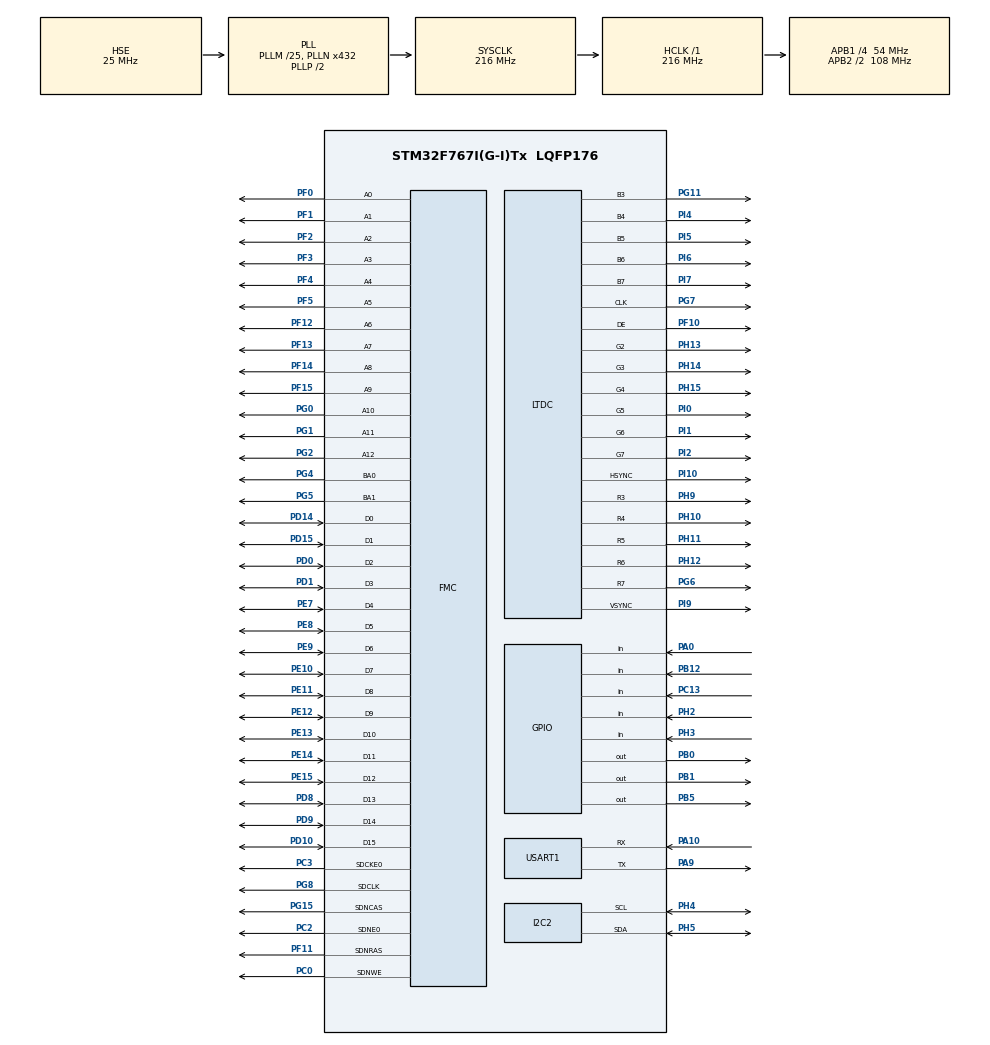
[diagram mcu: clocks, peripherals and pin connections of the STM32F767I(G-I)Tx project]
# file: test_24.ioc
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CORTEX_M7.MPU_Control=__NULL
CORTEX_M7.default_mode_Activation=1
DMA2D.ColorMode=DMA2D_OUTPUT_RGB565
FMC.CASLatency1=FMC_SDRAM_CAS_LATENCY_3
FMC.ColumnBitsNumber1=FMC_SDRAM_COLUMN_BITS_NUM_9
FMC.ExitSelfRefreshDelay1=8
FMC.LoadToActiveDelay1=2
FMC.RCDDelay1=2
FMC.RPDelay1=2
FMC.ReadBurst1=FMC_SDRAM_RBURST_ENABLE
FMC.ReadPipeDelay1=FMC_SDRAM_RPIPE_DELAY_1
FMC.RowCycleDelay1=6
FMC.SDClockPeriod1=FMC_SDRAM_CLOCK_PERIOD_2
FMC.SelfRefreshTime1=6
FMC.WriteRecoveryTime1=4
I2C2.I2C_Fall_Time=10
I2C2.I2C_Rise_Time=100
I2C2.Timing=0x60201E2B
LTDC.ActiveW=800
LTDC.Alpha_L0=255
LTDC.BlendingFactor1_L0=LTDC_BLENDING_FACTOR1_PAxCA
LTDC.BlendingFactor2_L0=LTDC_BLENDING_FACTOR2_PAxCA
LTDC.FBStartAdress_L0=0xc0000000
LTDC.HBP=88
LTDC.HFP=40
LTDC.HSync=48
LTDC.ImageHeight_L0=480
LTDC.ImageWidth_L0=800
LTDC.ImageWidth_L1=0
LTDC.PixelFormat_L0=LTDC_PIXEL_FORMAT_RGB565
LTDC.PixelFormat_L1=LTDC_PIXEL_FORMAT_RGB565
LTDC.VBP=32
LTDC.VFP=13
LTDC.VSync=3
LTDC.WindowX1_L0=800
LTDC.WindowY1_L0=480
Mcu.Family=STM32F7
Mcu.Name=STM32F767I(G-I)Tx
Mcu.Package=LQFP176
NVIC.PriorityGroup=NVIC_PRIORITYGROUP_2
NVIC.USART1_IRQn=true\:2\:2\:true\:false\:true\:true\:true\:true
PA0/WKUP.GPIO_PuPd=GPIO_PULLDOWN
PA0/WKUP.Signal=GPIO_Input
PA10.GPIO_PuPd=GPIO_PULLUP
PA10.GPIO_Speed=GPIO_SPEED_FREQ_HIGH
PA10.Mode=Asynchronous
PA10.Signal=USART1_RX
PA9.GPIO_ModeDefaultPP=GPIO_MODE_AF_PP
PA9.GPIO_PuPd=GPIO_PULLUP
PA9.GPIO_Speed=GPIO_SPEED_FREQ_HIGH
PA9.Mode=Asynchronous
PA9.Signal=USART1_TX
PB0.GPIO_PuPd=GPIO_PULLUP
PB0.GPIO_Speed=GPIO_SPEED_FREQ_HIGH
PB0.PinState=GPIO_PIN_SET
PB0.Signal=GPIO_Output
PB1.GPIO_PuPd=GPIO_PULLUP
PB1.GPIO_Speed=GPIO_SPEED_FREQ_HIGH
PB1.PinState=GPIO_PIN_SET
PB1.Signal=GPIO_Output
PB12.GPIO_PuPd=GPIO_PULLUP
PB12.Signal=GPIO_Input
PB5.GPIO_PuPd=GPIO_PULLUP
PB5.GPIO_Speed=GPIO_SPEED_FREQ_HIGH
PB5.Signal=GPIO_Output
PC0.GPIO_Mode=GPIO_MODE_AF_PP
PC0.GPIO_PuPd=GPIO_PULLUP
PC0.GPIO_Speed_High_Default=GPIO_SPEED_FREQ_HIGH
PC0.Signal=FMC_SDNWE
PC13.GPIO_Mode=GPIO_MODE_INPUT
PC13.GPIO_PuPd=GPIO_PULLUP
PC13.Signal=GPIO_Input
PC14/OSC32_IN.Mode=LSE-External-Oscillator
PC14/OSC32_IN.Signal=RCC_OSC32_IN
PC15/OSC32_OUT.Mode=LSE-External-Oscillator
PC15/OSC32_OUT.Signal=RCC_OSC32_OUT
PC2.GPIO_Mode=GPIO_MODE_AF_PP
PC2.GPIO_PuPd=GPIO_PULLUP
PC2.GPIO_Speed_High_Default=GPIO_SPEED_FREQ_HIGH
PC2.Mode=SdramChipSelect1_1
PC2.Signal=FMC_SDNE0
PC3.GPIO_Mode=GPIO_MODE_AF_PP
PC3.GPIO_PuPd=GPIO_PULLUP
PC3.GPIO_Speed_High_Default=GPIO_SPEED_FREQ_HIGH
PC3.Mode=SdramChipSelect1_1
PC3.Signal=FMC_SDCKE0
PD0.GPIO_Mode=GPIO_MODE_AF_PP
PD0.GPIO_PuPd=GPIO_PULLUP
PD0.GPIO_Speed_High_Default=GPIO_SPEED_FREQ_HIGH
PD0.Signal=FMC_D2_DA2
PD1.GPIO_Mode=GPIO_MODE_AF_PP
PD1.GPIO_PuPd=GPIO_PULLUP
PD1.GPIO_Speed_High_Default=GPIO_SPEED_FREQ_HIGH
PD1.Signal=FMC_D3_DA3
PD10.GPIO_Mode=GPIO_MODE_AF_PP
PD10.GPIO_PuPd=GPIO_PULLUP
PD10.GPIO_Speed_High_Default=GPIO_SPEED_FREQ_HIGH
PD10.Signal=FMC_D15_DA15
PD14.GPIO_Mode=GPIO_MODE_AF_PP
PD14.GPIO_PuPd=GPIO_PULLUP
PD14.GPIO_Speed_High_Default=GPIO_SPEED_FREQ_HIGH
PD14.Signal=FMC_D0_DA0
PD15.GPIO_Mode=GPIO_MODE_AF_PP
PD15.GPIO_PuPd=GPIO_PULLUP
PD15.GPIO_Speed_High_Default=GPIO_SPEED_FREQ_HIGH
PD15.Signal=FMC_D1_DA1
PD8.GPIO_Mode=GPIO_MODE_AF_PP
PD8.GPIO_PuPd=GPIO_PULLUP
PD8.GPIO_Speed_High_Default=GPIO_SPEED_FREQ_HIGH
PD8.Signal=FMC_D13_DA13
PD9.GPIO_Mode=GPIO_MODE_AF_PP
PD9.GPIO_PuPd=GPIO_PULLUP
PD9.GPIO_Speed_High_Default=GPIO_SPEED_FREQ_HIGH
PD9.Signal=FMC_D14_DA14
PE0.GPIO_Mode=GPIO_MODE_AF_PP
PE0.GPIO_PuPd=GPIO_PULLUP
PE0.GPIO_Speed_High_Default=GPIO_SPEED_FREQ_HIGH
PE0.Signal=FMC_NBL0
PE1.GPIO_Mode=GPIO_MODE_AF_PP
PE1.GPIO_PuPd=GPIO_PULLUP
PE1.GPIO_Speed_High_Default=GPIO_SPEED_FREQ_HIGH
PE1.Signal=FMC_NBL1
PE10.GPIO_Mode=GPIO_MODE_AF_PP
PE10.GPIO_PuPd=GPIO_PULLUP
PE10.GPIO_Speed_High_Default=GPIO_SPEED_FREQ_HIGH
PE10.Signal=FMC_D7_DA7
PE11.GPIO_Mode=GPIO_MODE_AF_PP
PE11.GPIO_PuPd=GPIO_PULLUP
PE11.GPIO_Speed_High_Default=GPIO_SPEED_FREQ_HIGH
PE11.Signal=FMC_D8_DA8
PE12.GPIO_Mode=GPIO_MODE_AF_PP
PE12.GPIO_PuPd=GPIO_PULLUP
PE12.GPIO_Speed_High_Default=GPIO_SPEED_FREQ_HIGH
PE12.Signal=FMC_D9_DA9
PE13.GPIO_Mode=GPIO_MODE_AF_PP
PE13.GPIO_PuPd=GPIO_PULLUP
PE13.GPIO_Speed_High_Default=GPIO_SPEED_FREQ_HIGH
PE13.Signal=FMC_D10_DA10
PE14.GPIO_Mode=GPIO_MODE_AF_PP
PE14.GPIO_PuPd=GPIO_PULLUP
PE14.GPIO_Speed_High_Default=GPIO_SPEED_FREQ_HIGH
PE14.Signal=FMC_D11_DA11
PE15.GPIO_Mode=GPIO_MODE_AF_PP
PE15.GPIO_PuPd=GPIO_PULLUP
PE15.GPIO_Speed_High_Default=GPIO_SPEED_FREQ_HIGH
PE15.Signal=FMC_D12_DA12
PE7.GPIO_Mode=GPIO_MODE_AF_PP
PE7.GPIO_PuPd=GPIO_PULLUP
PE7.GPIO_Speed_High_Default=GPIO_SPEED_FREQ_HIGH
PE7.Signal=FMC_D4_DA4
PE8.GPIO_Mode=GPIO_MODE_AF_PP
PE8.GPIO_PuPd=GPIO_PULLUP
PE8.GPIO_Speed_High_Default=GPIO_SPEED_FREQ_HIGH
PE8.Signal=FMC_D5_DA5
PE9.GPIO_Mode=GPIO_MODE_AF_PP
PE9.GPIO_PuPd=GPIO_PULLUP
PE9.GPIO_Speed_High_Default=GPIO_SPEED_FREQ_HIGH
PE9.Signal=FMC_D6_DA6
PF0.GPIO_Mode=GPIO_MODE_AF_PP
PF0.GPIO_PuPd=GPIO_PULLUP
PF0.GPIO_Speed_High_Default=GPIO_SPEED_FREQ_HIGH
PF0.Signal=FMC_A0
PF1.GPIO_Mode=GPIO_MODE_AF_PP
PF1.GPIO_PuPd=GPIO_PULLUP
PF1.GPIO_Speed_High_Default=GPIO_SPEED_FREQ_HIGH
PF1.Signal=FMC_A1
PF10.GPIO_PuPd=GPIO_NOPULL
PF10.GPIO_Speed=GPIO_SPEED_FREQ_HIGH
PF10.Mode=RGB565
PF10.Signal=LTDC_DE
PF11.GPIO_Mode=GPIO_MODE_AF_PP
PF11.GPIO_PuPd=GPIO_PULLUP
PF11.GPIO_Speed_High_Default=GPIO_SPEED_FREQ_HIGH
PF11.Signal=FMC_SDNRAS
PF12.GPIO_Mode=GPIO_MODE_AF_PP
PF12.GPIO_PuPd=GPIO_PULLUP
PF12.GPIO_Speed_High_Default=GPIO_SPEED_FREQ_HIGH
PF12.Signal=FMC_A6
PF13.GPIO_Mode=GPIO_MODE_AF_PP
PF13.GPIO_PuPd=GPIO_PULLUP
PF13.GPIO_Speed_High_Default=GPIO_SPEED_FREQ_HIGH
PF13.Signal=FMC_A7
PF14.GPIO_Mode=GPIO_MODE_AF_PP
PF14.GPIO_PuPd=GPIO_PULLUP
PF14.GPIO_Speed_High_Default=GPIO_SPEED_FREQ_HIGH
PF14.Signal=FMC_A8
PF15.GPIO_Mode=GPIO_MODE_AF_PP
PF15.GPIO_PuPd=GPIO_PULLUP
PF15.GPIO_Speed_High_Default=GPIO_SPEED_FREQ_HIGH
PF15.Signal=FMC_A9
PF2.GPIO_Mode=GPIO_MODE_AF_PP
PF2.GPIO_PuPd=GPIO_PULLUP
PF2.GPIO_Speed_High_Default=GPIO_SPEED_FREQ_HIGH
PF2.Signal=FMC_A2
PF3.GPIO_Mode=GPIO_MODE_AF_PP
PF3.GPIO_PuPd=GPIO_PULLUP
PF3.GPIO_Speed_High_Default=GPIO_SPEED_FREQ_HIGH
PF3.Signal=FMC_A3
PF4.GPIO_Mode=GPIO_MODE_AF_PP
PF4.GPIO_PuPd=GPIO_PULLUP
PF4.GPIO_Speed_High_Default=GPIO_SPEED_FREQ_HIGH
PF4.Signal=FMC_A4
PF5.GPIO_Mode=GPIO_MODE_AF_PP
PF5.GPIO_PuPd=GPIO_PULLUP
PF5.GPIO_Speed_High_Default=GPIO_SPEED_FREQ_HIGH
PF5.Signal=FMC_A5
PG0.GPIO_Mode=GPIO_MODE_AF_PP
PG0.GPIO_PuPd=GPIO_PULLUP
PG0.GPIO_Speed_High_Default=GPIO_SPEED_FREQ_HIGH
PG0.Signal=FMC_A10
PG1.GPIO_Mode=GPIO_MODE_AF_PP
PG1.GPIO_PuPd=GPIO_PULLUP
PG1.GPIO_Speed_High_Default=GPIO_SPEED_FREQ_HIGH
PG1.Signal=FMC_A11
PG11.GPIO_Mode=GPIO_MODE_AF_PP
PG11.GPIO_PuPd=GPIO_NOPULL
PG11.GPIO_Speed=GPIO_SPEED_FREQ_HIGH
PG11.Mode=RGB565
PG11.Signal=LTDC_B3
PG15.GPIO_Mode=GPIO_MODE_AF_PP
PG15.GPIO_PuPd=GPIO_PULLUP
PG15.GPIO_Speed_High_Default=GPIO_SPEED_FREQ_HIGH
PG15.Signal=FMC_SDNCAS
PG2.GPIO_Mode=GPIO_MODE_AF_PP
PG2.GPIO_PuPd=GPIO_PULLUP
PG2.GPIO_Speed_High_Default=GPIO_SPEED_FREQ_HIGH
PG2.Signal=FMC_A12
PG4.GPIO_Mode=GPIO_MODE_AF_PP
PG4.GPIO_PuPd=GPIO_PULLUP
PG4.GPIO_Speed_High_Default=GPIO_SPEED_FREQ_HIGH
PG4.Signal=FMC_A14_BA0
PG5.GPIO_Mode=GPIO_MODE_AF_PP
PG5.GPIO_PuPd=GPIO_PULLUP
PG5.GPIO_Speed_High_Default=GPIO_SPEED_FREQ_HIGH
PG5.Signal=FMC_A15_BA1
PG6.GPIO_Mode=GPIO_MODE_AF_PP
PG6.GPIO_PuPd=GPIO_NOPULL
PG6.GPIO_Speed=GPIO_SPEED_FREQ_HIGH
PG6.Mode=RGB565
PG6.Signal=LTDC_R7
PG7.GPIO_Mode=GPIO_MODE_AF_PP
PG7.GPIO_PuPd=GPIO_NOPULL
PG7.GPIO_Speed=GPIO_SPEED_FREQ_HIGH
PG7.Mode=RGB565
PG7.Signal=LTDC_CLK
PG8.GPIO_Mode=GPIO_MODE_AF_PP
PG8.GPIO_PuPd=GPIO_PULLUP
PG8.GPIO_Speed_High_Default=GPIO_SPEED_FREQ_HIGH
PG8.Signal=FMC_SDCLK
PH0/OSC_IN.Mode=HSE-External-Oscillator
PH0/OSC_IN.Signal=RCC_OSC_IN
PH1/OSC_OUT.Mode=HSE-External-Oscillator
PH1/OSC_OUT.Signal=RCC_OSC_OUT
PH10.GPIO_Mode=GPIO_MODE_AF_PP
PH10.GPIO_PuPd=GPIO_NOPULL
PH10.GPIO_Speed=GPIO_SPEED_FREQ_HIGH
PH10.Mode=RGB565
PH10.Signal=LTDC_R4
PH11.GPIO_Mode=GPIO_MODE_AF_PP
PH11.GPIO_PuPd=GPIO_NOPULL
PH11.GPIO_Speed=GPIO_SPEED_FREQ_HIGH
PH11.Mode=RGB565
PH11.Signal=LTDC_R5
PH12.GPIO_Mode=GPIO_MODE_AF_PP
PH12.GPIO_PuPd=GPIO_NOPULL
PH12.GPIO_Speed=GPIO_SPEED_FREQ_HIGH
PH12.Mode=RGB565
PH12.Signal=LTDC_R6
PH13.GPIO_Mode=GPIO_MODE_AF_PP
PH13.GPIO_PuPd=GPIO_NOPULL
PH13.GPIO_Speed=GPIO_SPEED_FREQ_HIGH
PH13.Mode=RGB565
PH13.Signal=LTDC_G2
PH14.GPIO_Mode=GPIO_MODE_AF_PP
PH14.GPIO_PuPd=GPIO_NOPULL
PH14.GPIO_Speed=GPIO_SPEED_FREQ_HIGH
PH14.Mode=RGB565
PH14.Signal=LTDC_G3
PH15.GPIO_Mode=GPIO_MODE_AF_PP
PH15.GPIO_PuPd=GPIO_NOPULL
PH15.GPIO_Speed=GPIO_SPEED_FREQ_HIGH
PH15.Mode=RGB565
PH15.Signal=LTDC_G4
PH2.GPIO_Mode=GPIO_MODE_INPUT
PH2.GPIO_PuPd=GPIO_PULLUP
PH2.Signal=GPIO_Input
PH3.GPIO_Mode=GPIO_MODE_INPUT
PH3.GPIO_PuPd=GPIO_PULLUP
PH3.Signal=GPIO_Input
PH4.GPIO_Mode=GPIO_MODE_AF_OD
PH4.GPIO_Pu=GPIO_PULLUP
PH4.GPIO_Speed=GPIO_SPEED_FREQ_HIGH
PH4.Mode=I2C
PH4.Signal=I2C2_SCL
PH5.GPIO_Mode=GPIO_MODE_AF_OD
PH5.GPIO_Pu=GPIO_PULLUP
PH5.GPIO_Speed=GPIO_SPEED_FREQ_HIGH
PH5.Mode=I2C
PH5.Signal=I2C2_SDA
PH9.GPIO_Mode=GPIO_MODE_AF_PP
PH9.GPIO_PuPd=GPIO_NOPULL
PH9.GPIO_Speed=GPIO_SPEED_FREQ_HIGH
PH9.Mode=RGB565
PH9.Signal=LTDC_R3
PI0.GPIO_Mode=GPIO_MODE_AF_PP
PI0.GPIO_PuPd=GPIO_NOPULL
PI0.GPIO_Speed=GPIO_SPEED_FREQ_HIGH
PI0.Mode=RGB565
PI0.Signal=LTDC_G5
PI1.GPIO_Mode=GPIO_MODE_AF_PP
PI1.GPIO_PuPd=GPIO_NOPULL
PI1.GPIO_Speed=GPIO_SPEED_FREQ_HIGH
PI1.Mode=RGB565
PI1.Signal=LTDC_G6
PI10.GPIO_Mode=GPIO_MODE_AF_PP
PI10.GPIO_PuPd=GPIO_NOPULL
PI10.GPIO_Speed=GPIO_SPEED_FREQ_HIGH
PI10.Mode=RGB565
PI10.Signal=LTDC_HSYNC
PI2.GPIO_Mode=GPIO_MODE_AF_PP
PI2.GPIO_PuPd=GPIO_NOPULL
PI2.GPIO_Speed=GPIO_SPEED_FREQ_HIGH
PI2.Mode=RGB565
PI2.Signal=LTDC_G7
PI4.GPIO_Mode=GPIO_MODE_AF_PP
PI4.GPIO_PuPd=GPIO_NOPULL
PI4.GPIO_Speed=GPIO_SPEED_FREQ_HIGH
PI4.Mode=RGB565
PI4.Signal=LTDC_B4
PI5.GPIO_Mode=GPIO_MODE_AF_PP
PI5.GPIO_PuPd=GPIO_NOPULL
PI5.GPIO_Speed=GPIO_SPEED_FREQ_HIGH
PI5.Mode=RGB565
PI5.Signal=LTDC_B5
PI6.GPIO_Mode=GPIO_MODE_AF_PP
PI6.GPIO_PuPd=GPIO_NOPULL
PI6.GPIO_Speed=GPIO_SPEED_FREQ_HIGH
PI6.Mode=RGB565
PI6.Signal=LTDC_B6
PI7.GPIO_Mode=GPIO_MODE_AF_PP
PI7.GPIO_PuPd=GPIO_NOPULL
PI7.GPIO_Speed=GPIO_SPEED_FREQ_HIGH
PI7.Mode=RGB565
PI7.Signal=LTDC_B7
PI9.GPIO_Mode=GPIO_MODE_AF_PP
PI9.GPIO_PuPd=GPIO_NOPULL
PI9.GPIO_Speed=GPIO_SPEED_FREQ_HIGH
PI9.Mode=RGB565
PI9.Signal=LTDC_VSYNC
ProjectManager.HeapSize=0x200
ProjectManager.StackSize=0x400
ProjectManager.TargetToolchain=MDK-ARM V5.32
RCC.AHBFreq_Value=216000000
RCC.APB1CLKDivider=RCC_HCLK_DIV4
RCC.APB1Freq_Value=54000000
RCC.APB1TimFreq_Value=108000000
RCC.APB2CLKDivider=RCC_HCLK_DIV2
RCC.APB2Freq_Value=108000000
RCC.APB2TimFreq_Value=216000000
RCC.CortexFreq_Value=216000000
RCC.HCLKFreq_Value=216000000
RCC.HSE_VALUE=25000000
RCC.HSI_VALUE=16000000
RCC.PLLM=25
RCC.PLLN=432
RCC.PLLSAIN=396
RCC.PLLSAIR=3
RCC.PLLSAIRDiv=RCC_PLLSAIDIVR_4
RCC.PLLSourceVirtual=RCC_PLLSOURCE_HSE
RCC.SYSCLKFreq_VALUE=216000000
RCC.SYSCLKSource=RCC_SYSCLKSOURCE_PLLCLK
RCC.USBFreq_Value=216000000
RCC.VCOOutputFreq_Value=432000000
SH.FMC_A0.0=FMC_A0,13b-sda1
SH.FMC_A1.0=FMC_A1,13b-sda1
SH.FMC_A10.0=FMC_A10,13b-sda1
SH.FMC_A11.0=FMC_A11,13b-sda1
SH.FMC_A12.0=FMC_A12,13b-sda1
SH.FMC_A14_BA0.0=FMC_BA0,FourSdramBanks1
SH.FMC_A15_BA1.0=FMC_BA1,FourSdramBanks1
SH.FMC_A2.0=FMC_A2,13b-sda1
SH.FMC_A3.0=FMC_A3,13b-sda1
SH.FMC_A4.0=FMC_A4,13b-sda1
SH.FMC_A5.0=FMC_A5,13b-sda1
SH.FMC_A6.0=FMC_A6,13b-sda1
SH.FMC_A7.0=FMC_A7,13b-sda1
SH.FMC_A8.0=FMC_A8,13b-sda1
SH.FMC_A9.0=FMC_A9,13b-sda1
SH.FMC_D0_DA0.0=FMC_D0,sd-16b-d1
SH.FMC_D10_DA10.0=FMC_D10,sd-16b-d1
SH.FMC_D11_DA11.0=FMC_D11,sd-16b-d1
SH.FMC_D12_DA12.0=FMC_D12,sd-16b-d1
SH.FMC_D13_DA13.0=FMC_D13,sd-16b-d1
SH.FMC_D14_DA14.0=FMC_D14,sd-16b-d1
SH.FMC_D15_DA15.0=FMC_D15,sd-16b-d1
SH.FMC_D1_DA1.0=FMC_D1,sd-16b-d1
SH.FMC_D2_DA2.0=FMC_D2,sd-16b-d1
SH.FMC_D3_DA3.0=FMC_D3,sd-16b-d1
SH.FMC_D4_DA4.0=FMC_D4,sd-16b-d1
SH.FMC_D5_DA5.0=FMC_D5,sd-16b-d1
SH.FMC_D6_DA6.0=FMC_D6,sd-16b-d1
SH.FMC_D7_DA7.0=FMC_D7,sd-16b-d1
SH.FMC_D8_DA8.0=FMC_D8,sd-16b-d1
SH.FMC_D9_DA9.0=FMC_D9,sd-16b-d1
SH.FMC_NBL0.0=FMC_NBL0
SH.FMC_NBL1.0=FMC_NBL1
SH.FMC_SDCLK.0=FMC_SDCLK,13b-sda1
SH.FMC_SDNCAS.0=FMC_SDNCAS,13b-sda1
SH.FMC_SDNRAS.0=FMC_SDNRAS,13b-sda1
SH.FMC_SDNWE.0=FMC_SDNWE,13b-sda1
USART1.VirtualMode-Asynchronous=VM_ASYNC
VP_DMA2D_VS_DMA2D.Mode=DMA2D_Activate
board=custom

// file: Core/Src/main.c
/* USER CODE BEGIN Header */
/**
  ******************************************************************************
  * @file           : main.c
  * @brief          : Main program body
  ******************************************************************************
  * @attention
  *
  * Copyright (c) 2022 STMicroelectronics.
  * All rights reserved.
  *
  * This software is licensed under terms that can be found in the LICENSE file
  * in the root directory of this software component.
  * If no LICENSE file comes with this software, it is provided AS-IS.
  *
  ******************************************************************************
  */
/* USER CODE END Header */
#include "main.h"
#include "dma2d.h"
#include "i2c.h"
#include "ltdc.h"
#include "usart.h"
#include "gpio.h"
#include "fmc.h"

/* USER CODE BEGIN Includes */
#include "stdio.h"
#include "lcd.h"
/* USER CODE END Includes */

void SystemClock_Config(void);

/* USER CODE BEGIN 0 */
//加入以下代码,支持printf函数,而不需要选择use MicroLIB
#if 1
#pragma import(__use_no_semihosting)
//解决HAL库使用时,某些情况可能报错的bug
int _ttywrch(int ch)
{
    ch=ch;
	return ch;
}
//标准库需要的支持函数
struct __FILE
{
	int handle;
	/* Whatever you require here. If the only file you are using is */
	/* standard output using printf() for debugging, no file handling */
	/* is required. */
};
/* FILE is typedef’ d in stdio.h. */
FILE __stdout;
//定义_sys_exit()以避免使用半主机模式
void _sys_exit(int x)
{
	x = x;
}
//重定义fputc函数
int fputc(int ch, FILE *f)
{
	while((USART1->ISR&0X40)==0);//循环发送,直到发送完毕
	USART1->TDR = (uint8_t) ch;
	return ch;
}
#endif
/* USER CODE END 0 */

int main(void)
{
  /* USER CODE BEGIN 1 */
	uint8_t key;		//按键值
	uint16_t i=0;		//LED循环
	uint8_t beepsta=0;		//蜂鸣器状态
  /* USER CODE END 1 */

  /* MCU Configuration--------------------------------------------------------*/

  /* Reset of all peripherals, Initializes the Flash interface and the Systick. */
  HAL_Init();

  /* Configure the system clock */
  SystemClock_Config();

  /* Initialize all configured peripherals */
  MX_GPIO_Init();
  MX_DMA2D_Init();
  MX_FMC_Init();
  MX_LTDC_Init();
  MX_USART1_UART_Init();
  MX_I2C2_Init();
  /* USER CODE BEGIN 2 */
	MX_FMC_Init();
	SDRAM_Initialization_Sequence(&hsdram1);//发送SDRAM初始化序列
	MX_LTDC_Init();
	LCD_Init();
	printf("初始化完毕");

	POINT_COLOR=RED;
	LCD_ShowString(30,50,200,16,16,(uint8_t *)"Apollo STM32F4/F7");
	LCD_ShowString(30,70,200,16,16,(uint8_t *)"PCF8574 TEST");
	LCD_ShowString(30,90,200,16,16,(uint8_t *)"ATOM@ALIENTEK");
	LCD_ShowString(30,130,200,16,16,(uint8_t *)"KEY0:BEEP ON/OFF");	//显示提示信息
	LCD_ShowString(30,150,200,16,16,(uint8_t *)"EXIO:DS1 ON/OFF");		//显示提示信息

	while(PCF8574_Init())		//检测不到PCF8574
	{
		LCD_ShowString(30,170,200,16,16,(uint8_t *)"PCF8574 Check Failed!");
		HAL_Delay(500);
		LCD_ShowString(30,170,200,16,16,(uint8_t *)"Please Check!      ");
		HAL_Delay(500);
		HAL_GPIO_TogglePin(LED0_GPIO_Port,LED0_Pin);//DS0闪烁
	}
	LCD_ShowString(30,170,200,16,16,(uint8_t *)"PCF8574 Ready!");
	POINT_COLOR=BLUE;//设置字体为蓝色

  /* USER CODE END 2 */

  /* Infinite loop */
  /* USER CODE BEGIN WHILE */
  while (1)
  {
	key=KEY_Scan(0);
	if(key==KEY0_PRES)//KEY0按下,读取字符串并显示
	{
		beepsta=!beepsta;					//蜂鸣器状态取反
		PCF8574_WriteBit(BEEP_IO,beepsta);	//控制蜂鸣器
	}
	if(PCF8574_INT==0)				//PCF8574的中断低电平有效
	{
		key=PCF8574_ReadBit(EX_IO);	//读取EXIO状态,同时清除PCF8574的中断输出(INT恢复高电平)
		if(key==0)HAL_GPIO_TogglePin(LED1_GPIO_Port,LED1_Pin);		//LED1状态取反
	}
	i++;
	HAL_Delay(10);
	if(i==20)
	{
		HAL_GPIO_TogglePin(LED0_GPIO_Port,LED0_Pin);  //提示系统正在运行
		i=0;
	}
    /* USER CODE END WHILE */

  }
}

void SystemClock_Config(void)
{
  RCC_OscInitTypeDef RCC_OscInitStruct = {0};
  RCC_ClkInitTypeDef RCC_ClkInitStruct = {0};

  /** Configure LSE Drive Capability
  */
  HAL_PWR_EnableBkUpAccess();

  /** Configure the main internal regulator output voltage
  */
  __HAL_RCC_PWR_CLK_ENABLE();
  __HAL_PWR_VOLTAGESCALING_CONFIG(PWR_REGULATOR_VOLTAGE_SCALE1);

  /** Initializes the RCC Oscillators according to the specified parameters
  * in the RCC_OscInitTypeDef structure.
  */
  RCC_OscInitStruct.OscillatorType = RCC_OSCILLATORTYPE_HSE;
  RCC_OscInitStruct.HSEState = RCC_HSE_ON;
  RCC_OscInitStruct.PLL.PLLState = RCC_PLL_ON;
  RCC_OscInitStruct.PLL.PLLSource = RCC_PLLSOURCE_HSE;
  RCC_OscInitStruct.PLL.PLLM = 25;
  RCC_OscInitStruct.PLL.PLLN = 432;
  RCC_OscInitStruct.PLL.PLLP = RCC_PLLP_DIV2;
  RCC_OscInitStruct.PLL.PLLQ = 2;
  RCC_OscInitStruct.PLL.PLLR = 2;
  if (HAL_RCC_OscConfig(&RCC_OscInitStruct) != HAL_OK)
  {
    Error_Handler();
  }

  /** Activate the Over-Drive mode
  */
  if (HAL_PWREx_EnableOverDrive() != HAL_OK)
  {
    Error_Handler();
  }

  /** Initializes the CPU, AHB and APB buses clocks
  */
  RCC_ClkInitStruct.ClockType = RCC_CLOCKTYPE_HCLK|RCC_CLOCKTYPE_SYSCLK
                              |RCC_CLOCKTYPE_PCLK1|RCC_CLOCKTYPE_PCLK2;
  RCC_ClkInitStruct.SYSCLKSource = RCC_SYSCLKSOURCE_PLLCLK;
  RCC_ClkInitStruct.AHBCLKDivider = RCC_SYSCLK_DIV1;
  RCC_ClkInitStruct.APB1CLKDivider = RCC_HCLK_DIV4;
  RCC_ClkInitStruct.APB2CLKDivider = RCC_HCLK_DIV2;

  if (HAL_RCC_ClockConfig(&RCC_ClkInitStruct, FLASH_LATENCY_7) != HAL_OK)
  {
    Error_Handler();
  }
}

void Error_Handler(void)
{
  __disable_irq();
  while (1)
  {
  }
}
